# STM32F411xx register map
File version: 1.0
Registers are 32-bit, read-write, reset 0x0 unless marked. A register's access mark holds for its fields unless they carry their own. Offsets are from the block's base; [hi:lo] are bit positions; {n}, {i} and the like mark numbered series; 'fields as' and 'values as' point back to an identical list.

## NVIC — Nested Vectored Interrupt Controller
Base 0xE000E000
0x04 ICTR ro — Interrupt Controller Type Register
  [3:0] INTLINESNUM — Total number of interrupt lines in groups
{0x100+4i} ISER{i} (i=0..2) — Interrupt Set-Enable Register
  [31:0] SETENA
{0x180+4i} ICER{i} (i=0..2) — Interrupt Clear-Enable Register
  [31:0] CLRENA
{0x200+4i} ISPR{i} (i=0..2) — Interrupt Set-Pending Register
  [31:0] SETPEND
{0x280+4i} ICPR{i} (i=0..2) — Interrupt Clear-Pending Register
  [31:0] CLRPEND
{0x300+4i} IABR{i} ro (i=0..2) — Interrupt Active Bit Register
  [31:0] ACTIVE
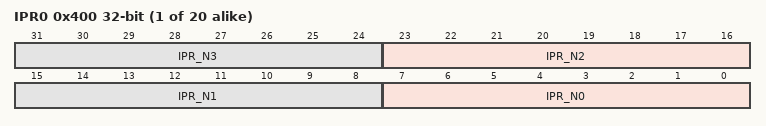
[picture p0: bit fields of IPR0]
{0x400+4i} IPR{i} (i=0..19) — Interrupt Priority Register
  [8n+7:8n] IPR_N{n} (n=0..3)
0xF00 STIR wo — Software Triggered Interrupt Register
  [8:0] INTID — interrupt to be triggered

## MPU — Memory Protection Unit -- OPTIONAL on ARMv7-M (__MPU_PRESENT). When present, includes 3 alias RBAR/RASR pairs so up to 4 regions can be programmed without re-writing RNR each time (verified against CMSIS core_cm3.h/core_cm4.h: MPU_TYPE_RALIASES=4).
Base 0xE000ED90
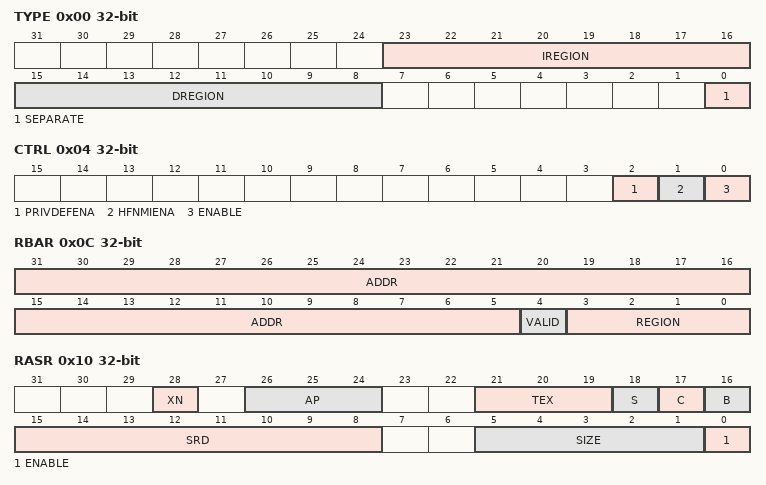
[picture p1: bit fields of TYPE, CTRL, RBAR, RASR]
0x00 TYPE ro — MPU Type Register
  [23:16] IREGION, [15:8] DREGION, [0] SEPARATE
0x04 CTRL — MPU Control Register
  [2] PRIVDEFENA, [1] HFNMIENA, [0] ENABLE
0x08 RNR — MPU Region Number Register
  [7:0] REGION
0x0C RBAR — MPU Region Base Address Register
  [31:5] ADDR, [4] VALID, [3:0] REGION
0x10 RASR — MPU Region Attribute and Size Register
  [28] XN, [26:24] AP, [21:19] TEX, [18] S, [17] C, [16] B, [15:8] SRD, [5:1] SIZE, [0] ENABLE
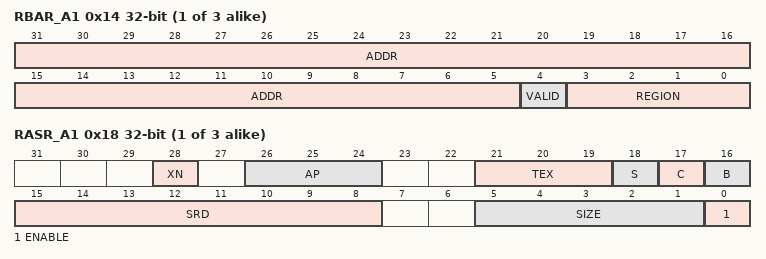
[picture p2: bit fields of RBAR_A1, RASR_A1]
{0xC+8i} RBAR_A{i} (i=1..3) — MPU Region Base Address Register alias
  [31:5] ADDR, [4] VALID, [3:0] REGION
{0x10+8i} RASR_A{i} (i=1..3) — MPU Region Attribute and Size Register alias
  fields as RASR

## SysTick — SysTick Timer. Identical register set on every Cortex-M core (ARMv6-M through current ARMv8-M).
Base 0xE000E010
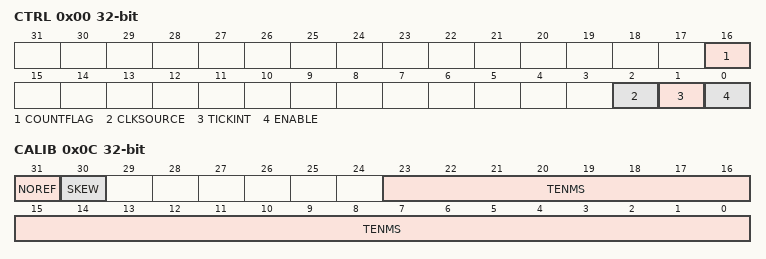
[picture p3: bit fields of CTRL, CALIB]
0x00 CTRL — SysTick Control and Status Register
  [16] COUNTFLAG ro, [2] CLKSOURCE, [1] TICKINT, [0] ENABLE
0x04 LOAD — SysTick Reload Value Register
  [23:0] RELOAD
0x08 VAL — SysTick Current Value Register. Any write clears it to 0 and clears COUNTFLAG.
  [23:0] CURRENT
0x0C CALIB ro — SysTick Calibration Value Register
  [31] NOREF, [30] SKEW, [23:0] TENMS

## CoreDebug — Core Debug Registers (DHCSR, DCRSR, DCRDR, DEMCR). Fixed ADIv5/CoreSight debug architecture -- identical on every Cortex-M core.
Base 0xE000EDF0
0x00 DHCSR — Debug Halting Control and Status Register
  [25] S_RESET_ST ro
  [24] S_RETIRE_ST ro
  [19] S_LOCKUP ro
  [18] S_SLEEP ro
  [17] S_HALT ro
  [16] S_REGRDY ro
  [31:16] DBGKEY wo — Write 0xA05F to enable write access to bits [15:0]; reads as 0
  [5] C_SNAPSTALL
  [3] C_MASKINTS
  [2] C_STEP
  [1] C_HALT
  [0] C_DEBUGEN
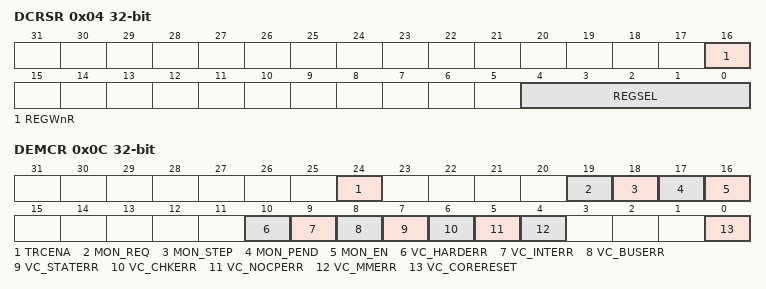
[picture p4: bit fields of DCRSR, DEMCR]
0x04 DCRSR wo — Debug Core Register Selector Register
  [16] REGWnR, [4:0] REGSEL
0x08 DCRDR — Debug Core Register Data Register
  [31:0] DBGTMP
0x0C DEMCR — Debug Exception and Monitor Control Register. On ARMv6-M only VC_CORERESET and TRCENA are architecturally defined; the fault-related VC_* bits and the monitor MON_* bits apply from ARMv7-M up (v6-M has no MemManage/BusFault/UsageFault/Debug-Monitor exception, so those control bits do not exist there -- included here for completeness/documentation, treat as reserved on v6-M).
  [24] TRCENA — Trace enable (DWT/ITM/ETM/TPIU) -- only meaningful where those blocks exist
  [19] MON_REQ — Debug Monitor request -- ARMv7-M and later only
  [18] MON_STEP — Debug Monitor step -- ARMv7-M and later only
  [17] MON_PEND — Debug Monitor pend -- ARMv7-M and later only
  [16] MON_EN — Debug Monitor enable -- ARMv7-M and later only
  [10] VC_HARDERR — Debug trap on HardFault exception
  [9] VC_INTERR — Debug trap on interrupt/exception service errors -- ARMv7-M and later only
  [8] VC_BUSERR — Debug trap on BusFault exception -- ARMv7-M and later only
  [7] VC_STATERR — Debug trap on UsageFault state error -- ARMv7-M and later only
  [6] VC_CHKERR — Debug trap on UsageFault caused by checking error -- ARMv7-M and later only
  [5] VC_NOCPERR — Debug trap on UsageFault caused by no coprocessor -- ARMv7-M and later only
  [4] VC_MMERR — Debug trap on MemManage exception -- ARMv7-M and later only
  [0] VC_CORERESET — Reset Vector Catch
